# D2522AA register map
Vendor: Dialog; Series: D2522AA; File version: 1.2
CPU: CM0 r1p0, little endian, MPU, FPU, 3 interrupt priority bits
Registers are 32-bit, read-write, reset 0x0 unless marked. A register's access mark holds for its fields unless they carry their own. Offsets are from the block's base; [hi:lo] are bit positions; {n}, {i} and the like mark numbered series.

## LCDC — LCDC registers
Base 0x30030000
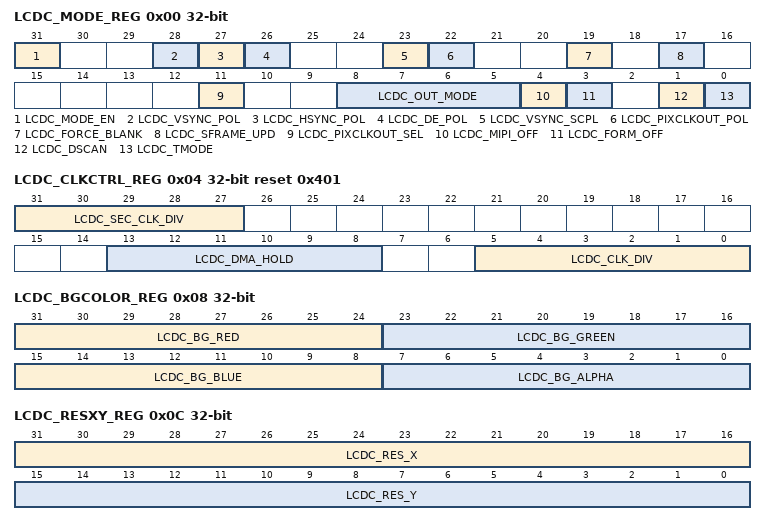
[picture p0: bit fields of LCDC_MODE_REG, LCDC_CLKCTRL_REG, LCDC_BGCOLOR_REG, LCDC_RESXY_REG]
0x00 LCDC_MODE_REG (reset mask 0x7FFFFFFF) — Display Mode
  [31] LCDC_MODE_EN — Mode register. 0 : disable 1 : enable
  [28] LCDC_VSYNC_POL — VSYNC polarity. 0: positive 1: negative
  [27] LCDC_HSYNC_POL — HSYNC polarity. 0: positive 1: negative
  [26] LCDC_DE_POL — DE polarity. 0: positive 1: negative
  [23] LCDC_VSYNC_SCPL — Set VSYNC for a single cycle per line. 0: disable 1: enable
  [22] LCDC_PIXCLKOUT_POL — Pixel clock out polarity. 0: positive 1: negative
  [19] LCDC_FORCE_BLANK — Forces output to blank. 0: disable 1: enable
  [17] LCDC_SFRAME_UPD — Single frame update. 0: disable 1: enable
  [11] LCDC_PIXCLKOUT_SEL — Selects the pixel out clock for the display. 0: based on the pixel pipeline clock 1: based on the format pipeline clock See also the LCDC_CLKCTRL_REG.
  [8:5] LCDC_OUT_MODE — Selection of the output mode 0000: Parallel RGB 1000: JDI MIP All the other values are reserved.
  [4] LCDC_MIPI_OFF — MIPI off. 0: disabled 1: enabled
  [3] LCDC_FORM_OFF — Formating off 0: disabled 1: enabled
  [1] LCDC_DSCAN — Double horizontal scan 0: disabled 1: enabled
  [0] LCDC_TMODE — Test mode 0: disabled 1: enabled
0x04 LCDC_CLKCTRL_REG reset 0x401 (reset mask 0x7FFFFFFF) — Clock Divider
  [31:27] LCDC_SEC_CLK_DIV — Secondary clock divider that generates the format pipeline clock. Source clock of this divider is the main clock of LCD controller. The period of the generated clock is defined as : (LCDC_SEC_CLK_DIV + 1) x period_of_main_clock.
  [13:8] LCDC_DMA_HOLD — Hold time before DMA activated.
  [5:0] LCDC_CLK_DIV — Clock divider that generates the pixel pipeline clock. Source clock of this divider is the format pipeline clock (see also LCDC_SEC_CLK_DIV). The period of the generated clock is defines as : LCDC_CLK_DIV x period_of_format_clk. A zero value gives division by one.
0x08 LCDC_BGCOLOR_REG (reset mask 0x7FFFFFFF) — Background Color
  [31:24] LCDC_BG_RED — Red color used as background.
  [23:16] LCDC_BG_GREEN — Green color used as background.
  [15:8] LCDC_BG_BLUE — Blue color used as background.
  [7:0] LCDC_BG_ALPHA — Alpha color used as background.
0x0C LCDC_RESXY_REG (reset mask 0x7FFFFFFF) — Resolution X,Y
  [31:16] LCDC_RES_X — Resolution X in pixels.
  [15:0] LCDC_RES_Y — Resolution Y in pixels.
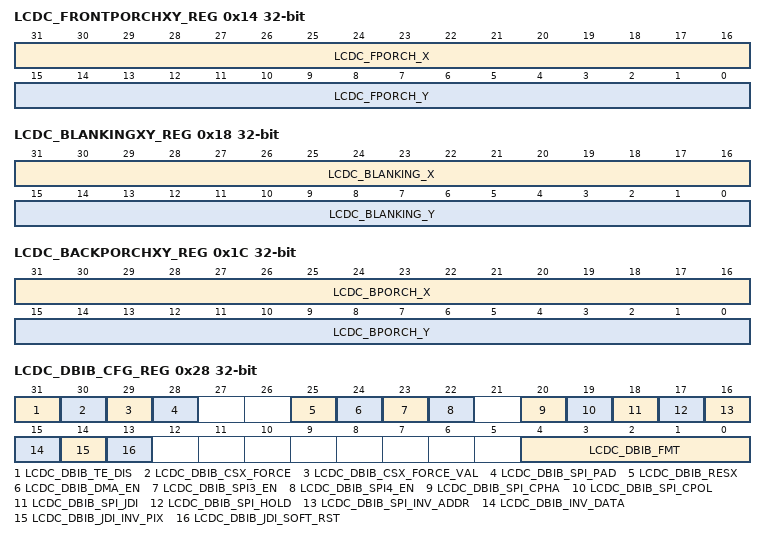
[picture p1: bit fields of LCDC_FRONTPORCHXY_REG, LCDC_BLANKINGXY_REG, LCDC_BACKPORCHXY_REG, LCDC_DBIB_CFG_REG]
0x14 LCDC_FRONTPORCHXY_REG (reset mask 0x7FFFFFFF) — Front Porch X and Y
  [31:16] LCDC_FPORCH_X — Front porch X (lines)
  [15:0] LCDC_FPORCH_Y — Front porch Y (pixel clocks)
0x18 LCDC_BLANKINGXY_REG (reset mask 0x7FFFFFFF) — Blanking X and Y
  [31:16] LCDC_BLANKING_X — Blanking period X (VSYNC lines)
  [15:0] LCDC_BLANKING_Y — Blanking period Y (HSYNC pulse length)
0x1C LCDC_BACKPORCHXY_REG (reset mask 0x7FFFFFFF) — Back Porch X and Y
  [31:16] LCDC_BPORCH_X — Back porch X (lines)
  [15:0] LCDC_BPORCH_Y — Back porch Y (pixel clocks)
0x28 LCDC_DBIB_CFG_REG (reset mask 0x7FFFFFFF) — MIPI Config Register
  [31] LCDC_DBIB_TE_DIS — Disable the sampling of the tearing effect signal, which is provided by the LCD device. 0: the tearing effect signal is sampled 1: the tearing effect signal is not sampled.
  [30] LCDC_DBIB_CSX_FORCE — Forces the DBIB CSX value. When is enabled the DBIB CSX takes the value of the LCDC_DBIB_CSX_FORCE_VAL. 0 : disable 1 : enable
  [29] LCDC_DBIB_CSX_FORCE_VAL — Value of DBIB CSX to be forced, if bit 30 is set. Defines also the active level of the DBIB CSX even if the bit 30 is not set.
  [28] LCDC_DBIB_SPI_PAD — Data padding : 0 : disable 1 : enable
  [25] LCDC_DBIB_RESX — DBIB RESX, reset signal for MIPI DBIB display.
  [24] LCDC_DBIB_DMA_EN — Send pixels from DMA to DBIB display. 0 : disable 1 : enable
  [23] LCDC_DBIB_SPI3_EN — Enable SPI3 interface. 0 : disable 1 : enable
  [22] LCDC_DBIB_SPI4_EN — Enable SPI4 interface. 0 : disable 1 : enable
  [20] LCDC_DBIB_SPI_CPHA — Sets the data phase for the SPI interface
  [19] LCDC_DBIB_SPI_CPOL — Sets the polarity of the clock (SCL)
  [18] LCDC_DBIB_SPI_JDI — Enables the line addressing between the horizontal lines (JDI SPI output format). 0 : disable 1 : enable
  [17] LCDC_DBIB_SPI_HOLD — Enables the command HOLD mode of operation. Commands and data transmissions binding. 0 : disable 1 : enable
  [16] LCDC_DBIB_SPI_INV_ADDR — Enables horizontal line address inversion. 0 : disable 1 : enable
  [15] LCDC_DBIB_INV_DATA — Data inversion 0 : disable 1 : enable
  [14] LCDC_DBIB_JDI_INV_PIX — MSB-LSB bit selection for JDI parallel interface 0 : disable (MSB - LSB) 1 : enable (LSB -MSB)
  [13] LCDC_DBIB_JDI_SOFT_RST — JDI timing generation soft reset. 0 : disable 1 : enable
  [4:0] LCDC_DBIB_FMT — Defines the output format and depends of the type of the output interface. For the SPI3 and the SPI4 are supported the following formats: 0x10 : RGB332 0x11 : RGB444 0x12 : RGB565 0x13 : RGB666 0x14 : RGB888 For the SPI4 only are supported additionally the following formats: 0x06 : RGB111-1 {2b00, R(n), G(n), B(n), R(n+1), G(n+1), B(n+1)} 0x07 : RGB111-2 {R(n), G(n), B(n), 1b0, R(n+1), G(n+1), B(n+1), 1b0} 0x08 : RGB111-3 {R(n), G(n), B(n), R(n+1), G(n+1), B(n+1), R(n+2), G(n+2), B(n+2),... } 0x09 : RGB111-4 {D(n), D(n+1), D(n+2),...} For the JDI parallel interface should be used the format : 0x0A : RGB222
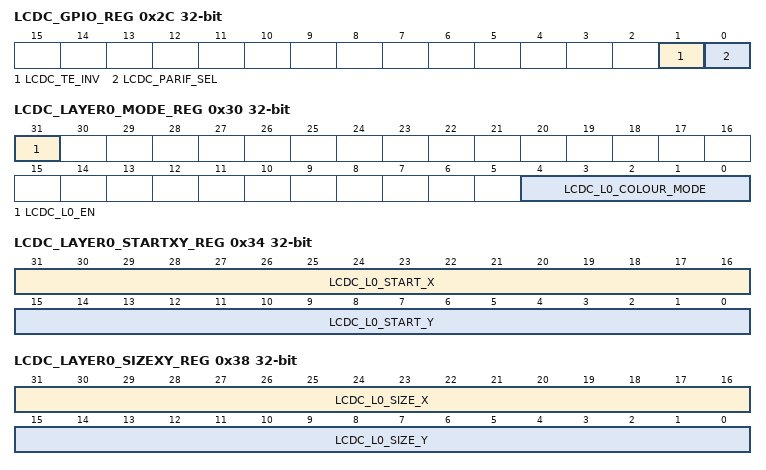
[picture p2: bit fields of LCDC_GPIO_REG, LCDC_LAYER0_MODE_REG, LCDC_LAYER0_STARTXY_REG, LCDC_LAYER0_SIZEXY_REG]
0x2C LCDC_GPIO_REG — General Purpose IO (2-bits)
  [1] LCDC_TE_INV — Applies an inversion on the TE (tearing effect) signal. 0 : the inversion is not applied on the TE signal 1 : the inversion is applied on TE signal
  [0] LCDC_PARIF_SEL — Selection of the parallel interface type that is forwarded to the gpio pins. 0 : JDI interface signals 1 : Clasic parallel interface
0x30 LCDC_LAYER0_MODE_REG (reset mask 0x7FFFFFFF) — Layer0 Mode
  [31] LCDC_L0_EN — Enable layer. 0 : disable 1 : enable
  [4:0] LCDC_L0_COLOUR_MODE — Colour Mode: 00001: 16-bit RGBX5551 color format, 00010: 32-bit RGBX8888 color format, 00100: 8-bit RGB332 color format, 00101: 16-bit RGB565 color format, 00110: 32-bit XRGB8888, 00111: L8 Grayscale/Palette format, 01000: L1 Grayscale/Palette format, 01001: L4 Grayscale/Palette format, 01101: ABGR8888, 01110: BGRA8888
0x34 LCDC_LAYER0_STARTXY_REG (reset mask 0x7FFFFFFF) — Layer0 Start XY
  [31:16] LCDC_L0_START_X — Start X (offset pixels)
  [15:0] LCDC_L0_START_Y — Start Y (offset pixels)
0x38 LCDC_LAYER0_SIZEXY_REG (reset mask 0x7FFFFFFF) — Layer0 Size XY
  [31:16] LCDC_L0_SIZE_X — Size X (Size of layer in pixels)
  [15:0] LCDC_L0_SIZE_Y — Size Y (Size of layer in pixels)
0x3C LCDC_LAYER0_BASEADDR_REG (reset mask 0x7FFFFFFF) — Layer0 Base Addr
  [31:0] LCDC_L0_FB_ADDR — Base Address of the frame buffer
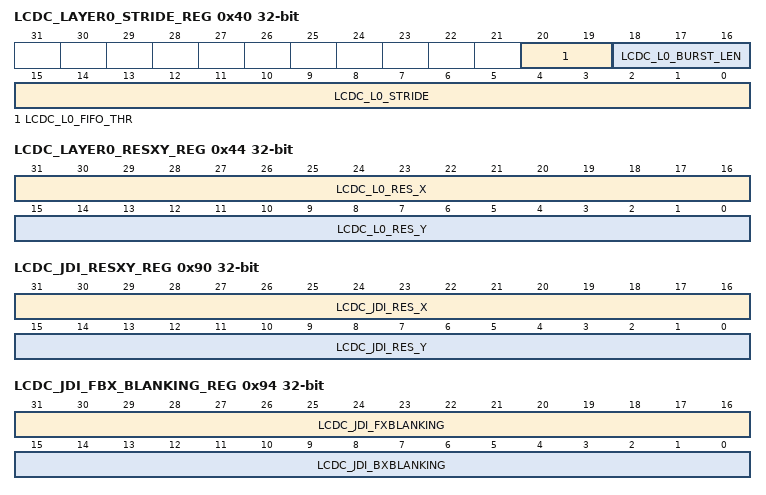
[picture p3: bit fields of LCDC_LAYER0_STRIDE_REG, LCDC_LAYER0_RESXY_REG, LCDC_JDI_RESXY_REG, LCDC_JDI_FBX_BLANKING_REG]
0x40 LCDC_LAYER0_STRIDE_REG — Layer0 Stride
  [20:19] LCDC_L0_FIFO_THR — Layer dma fifo threshold burst start 00: half fifo (default) 01: 2 burst size 10: 4 burst size 11: 8 burst size
  [18:16] LCDC_L0_BURST_LEN — Layer burst length 000: 16-beats (default) 001: 2-beats 010: 4-beats 011: 8-beats 100: 16-beats
  [15:0] LCDC_L0_STRIDE — Layer Stride (distance from line to line in bytes)
0x44 LCDC_LAYER0_RESXY_REG (reset mask 0x7FFFFFFF) — Layer0 Res XY
  [31:16] LCDC_L0_RES_X — Resolution X (Resolution of layer in pixels)
  [15:0] LCDC_L0_RES_Y — Resolution Y (Resolution of layer in pixels)
0x90 LCDC_JDI_RESXY_REG (reset mask 0x7FFFFFFF) — Resolution XY for the JDI parallel I/F
  [31:16] LCDC_JDI_RES_X — Number of horizontal transfers. Should be equal to the half of the horizontal resolution (in pixels).
  [15:0] LCDC_JDI_RES_Y — Number of vertical transfers. Should be equal to the double of the vertical resolution (in lines).
0x94 LCDC_JDI_FBX_BLANKING_REG (reset mask 0x7FFFFFFF) — Horizontal front/back blanking (hck half periods)
  [31:16] LCDC_JDI_FXBLANKING — Horizontal front blanking as a number of hck half periods
  [15:0] LCDC_JDI_BXBLANKING — Horizontal back blanking as a number of hck half periods
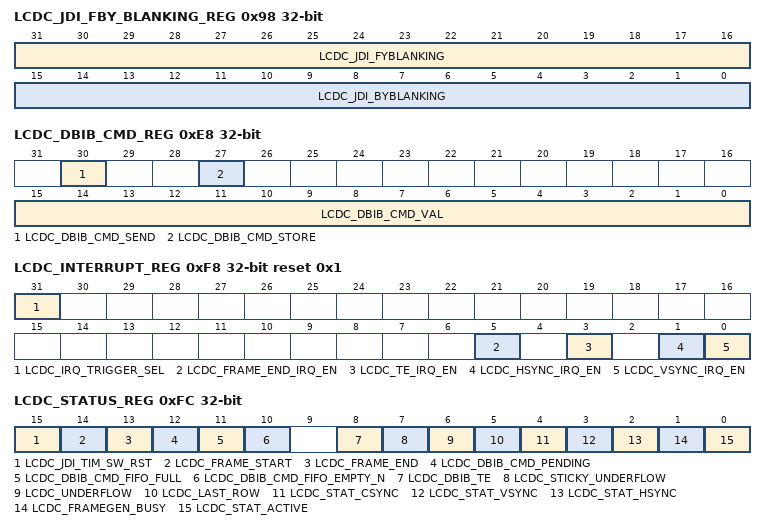
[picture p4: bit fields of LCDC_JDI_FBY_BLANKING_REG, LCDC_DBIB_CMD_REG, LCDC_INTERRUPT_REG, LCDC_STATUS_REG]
0x98 LCDC_JDI_FBY_BLANKING_REG (reset mask 0x7FFFFFFF) — Vertical front/back blanking (vck half periods)
  [31:16] LCDC_JDI_FYBLANKING — Vertical front blanking as a number of vck half periods
  [15:0] LCDC_JDI_BYBLANKING — Vertical back blanking as a number of vck half periods
0x9C LCDC_JDI_HCK_WIDTH_REG (reset mask 0x7FFFFFFF) — HCK high/low width
  [31:0] LCDC_JDI_HCK_WIDTH — Number of formal pipeline clock cycles that define the half period of the of the HCK (high and low width). The minimum allowed value is 2.
0xA0 LCDC_JDI_XRST_WIDTH_REG (reset mask 0x7FFFFFFF) — XRST width
  [31:0] LCDC_JDI_XRST_WIDTH — Number of format pipeline clock cycles of XRST width
0xA4 LCDC_JDI_VST_DELAY_REG (reset mask 0x7FFFFFFF) — XRST-to-VST delay
  [31:0] LCDC_JDI_VST_DELAY — XRST-to-VST delay in format pipeline clock cycles
0xA8 LCDC_JDI_VST_WIDTH_REG (reset mask 0x7FFFFFFF) — VST width
  [31:0] LCDC_JDI_VST_WIDTH — VST width in format pipeline clock cycles
0xAC LCDC_JDI_VCK_DELAY_REG (reset mask 0x7FFFFFFF) — XRST-to-VCK delay
  [31:0] LCDC_JDI_VCK_DELAY — XRST-to-VCK delay in format pipeline clock cycles
0xB0 LCDC_JDI_HST_DELAY_REG (reset mask 0x7FFFFFFF) — VCK-to-HST delay
  [31:0] LCDC_JDI_HST_DELAY — VCK-to-HST delay in format pipeline clock cycles
0xB4 LCDC_JDI_HST_WIDTH_REG (reset mask 0x7FFFFFFF) — HST width
  [31:0] LCDC_JDI_HST_WIDTH — HST width in format pipeline clock cycles
0xB8 LCDC_JDI_ENB_START_HLINE_REG (reset mask 0x7FFFFFFF) — ENB start horizontal line
  [31:0] LCDC_JDI_ENB_START_HLINE — The number of the first horizontal line where the ENB signal is asserted
0xBC LCDC_JDI_ENB_END_HLINE_REG (reset mask 0x7FFFFFFF) — ENB end horizontal line
  [31:0] LCDC_JDI_ENB_END_HLINE — The number of the last horizontal line where the ENB signal is asserted
0xC0 LCDC_JDI_ENB_START_CLK_REG (reset mask 0x7FFFFFFF) — ENB start delay
  [31:0] LCDC_JDI_ENB_START_CLK — Defines the number of the HCK half periods that should take place after a transtion in the VCK and before to be enabled of the ENB.
0xC4 LCDC_JDI_ENB_WIDTH_CLK_REG (reset mask 0x7FFFFFFF) — ENB width
  [31:0] LCDC_JDI_ENB_WIDTH_CLK — ENB (high) width in HCK half periods
0xE8 LCDC_DBIB_CMD_REG — MIPI DBIB Command Register
  [30] LCDC_DBIB_CMD_SEND — Send command to the DBI interface
  [27] LCDC_DBIB_CMD_STORE — This bit has meaning only when LCDC_DBIB_CFG_REG[LCDC_DBIB_SPI_JDI] = 1. When is enabled, stores the LCDC_DBIB_CMD_VAL to the register that keeps the Y position.
  [15:0] LCDC_DBIB_CMD_VAL — Data to send to the DBI interface
0xF4 LCDC_IDREG_REG reset 0x7FFFFFFF (reset mask 0x7FFFFFFF) — Identification Register
  [31:0] LCDC_ID ro — Identification register
0xF8 LCDC_INTERRUPT_REG reset 0x1 (reset mask 0x7FFFFFFF) — Interrupt Register
  [31] LCDC_IRQ_TRIGGER_SEL — IRQ trigger control 0: Level triggering 1: Edge triggering In the case of the level triggering, the request remains active in the LCDC until to be cleared. The request can be cleared by performing a write access in the LCDC_INTERRUPT_REG. This is not required in the case of the edge triggering.
  [5] LCDC_FRAME_END_IRQ_EN — Continuous mode: frame end. Single mode: frame end or idle.
  [3] LCDC_TE_IRQ_EN — TE interrupt enable. See also the configuration bit LCDC_DBIB_CFG_REG[LCDC_DBIB_TE_DIS]
  [1] LCDC_HSYNC_IRQ_EN — HSYNC interrupt enabled
  [0] LCDC_VSYNC_IRQ_EN — VSYNC or TE interrupt enabled. See also the configuration bit LCDC_DBIB_CFG_REG[LCDC_DBIB_TE_DIS] for the TE signal.
0xFC LCDC_STATUS_REG — Status Register
  [15] LCDC_JDI_TIM_SW_RST ro — JDI timing generation soft reset (active high)
  [14] LCDC_FRAME_START ro — Frame start (active high)
  [13] LCDC_FRAME_END ro — Frame end (active high)
  [12] LCDC_DBIB_CMD_PENDING ro — Transferring of command in progress. 0: idle 1: in progress
  [11] LCDC_DBIB_CMD_FIFO_FULL ro — Command fifo full indication. 0: is not full 1: is full
  [10] LCDC_DBIB_CMD_FIFO_EMPTY_N ro — Command fifo empty indication (negative) 0: the fifo is empty 1: the fifo is not empty
  [8] LCDC_DBIB_TE ro — The DBIB tearing effect signal
  [7] LCDC_STICKY_UNDERFLOW ro — Sticky underflow(clear with write in the LCDC_INTERRUPT_REG) 0: There is no underflow 1: Underflow has been detected.Remains high until to be cleared by performing a write access on the register LCDC_INTERRUPT_REG.
  [6] LCDC_UNDERFLOW ro — Underflow on the current transfer. 0: There is no underflow 1: Underflow has been detected.
  [5] LCDC_LAST_ROW ro — Last row (Last row is currently displayed)
  [4] LCDC_STAT_CSYNC ro — CSYNC signal level
  [3] LCDC_STAT_VSYNC ro — VSYNC signal level
  [2] LCDC_STAT_HSYNC ro — HSYNC signal level
  [1] LCDC_FRAMEGEN_BUSY ro — The frame generator is busy (active high).
  [0] LCDC_STAT_ACTIVE ro — Active (When not in vertical blanking)
0x184 LCDC_CRC_REG (reset mask 0x7FFFFFFF) — CRC check
  [31:0] LCDC_CRC ro — CRC check.
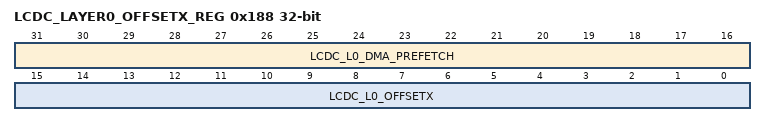
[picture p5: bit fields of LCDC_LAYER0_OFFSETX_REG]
0x188 LCDC_LAYER0_OFFSETX_REG (reset mask 0x7FFFFFFF) — Layer0 OffsetX and DMA prefetch
  [31:16] LCDC_L0_DMA_PREFETCH — DMA fifo prefetch level (range: 0-4) 0x0 : Prefetch mechanism is disabled 0x1 : Prefetch at least 44 bytes 0x2 : Prefetch at least 84 bytes 0x3 : Prefetch at least 116 bytes 0x4 : Prefetch at least 108 bytes Any other value : Reserved
  [15:0] LCDC_L0_OFFSETX — Offset X (negative) of X start pixel (range [n-1,0], n : pixels /8)
